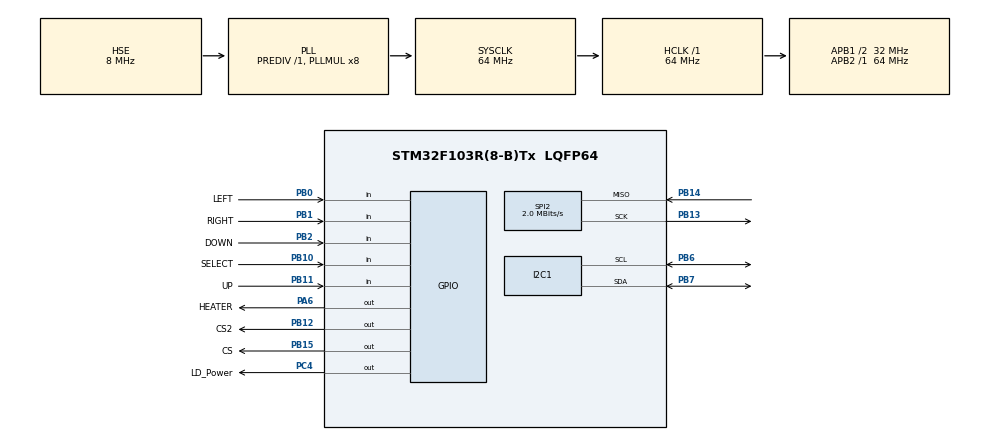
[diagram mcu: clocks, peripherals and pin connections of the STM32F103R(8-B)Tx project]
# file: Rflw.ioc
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FREERTOS.INCLUDE_xQueueGetMutexHolder=1
FREERTOS.Mutexes01=I2CMutex,Dynamic,NULL;xLCDMutex,Dynamic,NULL;SPIMutex,Dynamic,NULL
FREERTOS.Tasks01=systemMonitor,3,128,systemMonitorTask,Default,NULL,Dynamic,NULL,NULL;input,-2,128,inputTask,As external,NULL,Dynamic,NULL,NULL;menu,-3,128,menuTask,As external,NULL,Dynamic,NULL,NULL;control,1,128,controlTask,As external,NULL,Dynamic,NULL,NULL;LCD,-3,128,LCDTask,As external,NULL,Dynamic,NULL,NULL
FREERTOS.configCHECK_FOR_STACK_OVERFLOW=1
FREERTOS.configTOTAL_HEAP_SIZE=5120
I2C1.I2C_Mode=I2C_Fast
Mcu.Family=STM32F1
Mcu.Name=STM32F103R(8-B)Tx
Mcu.Package=LQFP64
NVIC.PriorityGroup=NVIC_PRIORITYGROUP_4
NVIC.SPI2_IRQn=true\:10\:0\:true\:false\:true\:true\:true\:true
NVIC.TIM1_UP_IRQn=true\:0\:0\:false\:false\:true\:false\:false\:true
NVIC.TimeBase=TIM1_UP_IRQn
NVIC.TimeBaseIP=TIM1
PA13.Mode=Trace_Asynchronous_SW
PA13.Signal=SYS_JTMS-SWDIO
PA14.Mode=Trace_Asynchronous_SW
PA14.Signal=SYS_JTCK-SWCLK
PA6.GPIO_Label=HEATER
PA6.PinState=GPIO_PIN_SET
PA6.Signal=GPIO_Output
PB0.GPIO_Label=LEFT
PB0.Signal=GPIO_Input
PB1.GPIO_Label=RIGHT
PB1.Signal=GPIO_Input
PB10.GPIO_Label=SELECT
PB10.GPIO_PuPd=GPIO_PULLUP
PB10.Signal=GPIO_Input
PB11.GPIO_Label=UP
PB11.GPIO_PuPd=GPIO_PULLUP
PB11.Signal=GPIO_Input
PB12.GPIO_Label=CS2
PB12.GPIO_Speed=GPIO_SPEED_FREQ_HIGH
PB12.PinState=GPIO_PIN_SET
PB12.Signal=GPIO_Output
PB13.Mode=RX_Only_Simplex_Unidirect_Master
PB13.Signal=SPI2_SCK
PB14.Mode=RX_Only_Simplex_Unidirect_Master
PB14.Signal=SPI2_MISO
PB15.GPIO_Label=CS
PB15.GPIO_Speed=GPIO_SPEED_FREQ_HIGH
PB15.PinState=GPIO_PIN_SET
PB15.Signal=GPIO_Output
PB2.GPIO_Label=DOWN
PB2.GPIO_PuPd=GPIO_PULLUP
PB2.Signal=GPIO_Input
PB3.Mode=Trace_Asynchronous_SW
PB3.Signal=SYS_JTDO-TRACESWO
PB6.Mode=I2C
PB6.Signal=I2C1_SCL
PB7.Mode=I2C
PB7.Signal=I2C1_SDA
PC14-OSC32_IN.Mode=LSE-External-Oscillator
PC14-OSC32_IN.Signal=RCC_OSC32_IN
PC15-OSC32_OUT.Mode=LSE-External-Oscillator
PC15-OSC32_OUT.Signal=RCC_OSC32_OUT
PC4.GPIO_Label=LD_Power
PC4.GPIO_ModeDefaultOutputPP=GPIO_MODE_OUTPUT_OD
PC4.PinState=GPIO_PIN_SET
PC4.Signal=GPIO_Output
PD0-OSC_IN.Mode=HSE-External-Oscillator
PD0-OSC_IN.Signal=RCC_OSC_IN
PD1-OSC_OUT.Mode=HSE-External-Oscillator
PD1-OSC_OUT.Signal=RCC_OSC_OUT
ProjectManager.HeapSize=0x200
ProjectManager.StackSize=0x400
ProjectManager.TargetToolchain=STM32CubeIDE
RCC.AHBFreq_Value=64000000
RCC.APB1CLKDivider=RCC_HCLK_DIV2
RCC.APB1Freq_Value=32000000
RCC.APB1TimFreq_Value=64000000
RCC.APB2Freq_Value=64000000
RCC.APB2TimFreq_Value=64000000
RCC.EnbaleCSS=true
RCC.HCLKFreq_Value=64000000
RCC.PLLMUL=RCC_PLL_MUL8
RCC.PLLSourceVirtual=RCC_PLLSOURCE_HSE
RCC.SYSCLKFreq_VALUE=64000000
RCC.SYSCLKSource=RCC_SYSCLKSOURCE_PLLCLK
RCC.USBFreq_Value=64000000
SPI2.BaudRatePrescaler=SPI_BAUDRATEPRESCALER_16
SPI2.CalculateBaudRate=2.0 MBits/s
SPI2.DataSize=SPI_DATASIZE_16BIT
SPI2.Direction=SPI_DIRECTION_2LINES_RXONLY
SPI2.Mode=SPI_MODE_MASTER
SPI2.VirtualType=VM_MASTER
VP_FREERTOS_VS_CMSIS_V1.Mode=CMSIS_V1
VP_SYS_VS_tim1.Mode=TIM1
board=custom

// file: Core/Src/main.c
/* USER CODE BEGIN Header */
/**
  ******************************************************************************
  * @file           : main.c
  * @brief          : Main program body
  ******************************************************************************
  * @attention
  *
  * <h2><center>&copy; Copyright (c) 2019 STMicroelectronics.
  * All rights reserved.</center></h2>
  *
  * This software component is licensed by ST under BSD 3-Clause license,
  * the "License"; You may not use this file except in compliance with the
  * License. You may obtain a copy of the License at:
  *                        opensource.org/licenses/BSD-3-Clause
  *
  ******************************************************************************
  */
/* USER CODE END Header */

#include "main.h"
#include "FreeRTOS.h"
#include "task.h"
#include "queue.h"
#include "semphr.h"

#include "config.h"

I2C_HandleTypeDef hi2c1;

SPI_HandleTypeDef hspi2;

#ifdef ENABLE_WWDG
WWDG_HandleTypeDef hwwdg;
#endif /* ENABLE_WWDG */

TaskHandle_t systemMonitorHandle;
TaskHandle_t inputHandle;
TaskHandle_t menuHandle;
TaskHandle_t controlHandle;
TaskHandle_t LCDHandle;

void SystemClock_Config(void);
static void MX_GPIO_Init(void);
static void MX_I2C1_Init(void);
static void MX_SPI2_Init(void);
#ifdef ENABLE_WWDG
static void MX_WWDG_Init(void);
#endif /* ENABLE_WWDG */
void systemMonitorTask(void * argument);
extern void vInputTask(void * argument);
extern void vMenuTask(void * argument);
extern void vControlTask(void * argument);
extern void vLCDTask(void * argument);

void InitSystem(void) {
	SystemClock_Config();

	MX_GPIO_Init();
	MX_I2C1_Init();
	MX_SPI2_Init();
	#ifdef ENABLE_WWDG
	MX_WWDG_Init();
	#endif /* ENABLE_WWDG */

//	HAL_SPI_RegisterCallback();
}

void InitOS(void) {
	xSystemMonitorTask = xTaskCreateStatic(systemMonitorTask, SYSTEM_MONITOR_NAME, SYSTEM_MONITOR_STACK_SIZE, NULL, SYSTEM_MONITOR_PRIORITY, xSystemMonitorStack, &xSystemMonitorBuffer);

	xInputHandlerTask = xTaskCreateStatic(vInputTask, INPUT_HANDLER_NAME, INPUT_HANDLER_STACK_SIZE, NULL, INPUT_HANDLER_PRIORITY, xInputHandlerStack, &xInputHandlerBuffer);

	xLCDTask = xTaskCreateStatic(vLCDTask, LCD_NAME, LCD_STACK_SIZE, NULL, LCD_PRIORITY, xLCDStack, &xLCDBuffer);

	xMenuTask = xTaskCreateStatic(vMenuTask, MENU_NAME, MENU_STACK_SIZE, NULL, MENU_PRIORITY, xMenuStack, &xMenuBuffer);

	xControlTask = xTaskCreateStatic(vControlTask, CONTROL_NAME, CONTROL_STACK_SIZE, NULL, CONTROL_PRIORITY, xControlStack, &xControlBuffer);

	xControlTask =  xTaskCreateStatic(vControlTask, CONTROL_NAME, CONTROL_STACK_SIZE, NULL, CONTROL_PRIORITY, xControlStack, &xControlBuffer);

	xI2CMutex = xSemaphoreCreateMutexStatic(&xI2CMutexBuffer);

	xSPIMutex = xSemaphoreCreateMutexStatic(&xSPIMutexBuffer);

	xLCDMutex = xSemaphoreCreateMutexStatic(&xLCDMutexBuffer);

	modeEventGroup = xEventGroupCreate();
	stateEventGroup = xEventGroupCreate();

	/* Start scheduler */
	vTaskStartScheduler();
}

void SystemClock_Config(void) {
	RCC_OscInitTypeDef RCC_OscInitStruct = {0};
	RCC_ClkInitTypeDef RCC_ClkInitStruct = {0};

	/** Initializes the CPU, AHB and APB busses clocks
	 */
	RCC_OscInitStruct.OscillatorType = RCC_OSCILLATORTYPE_HSE;
	RCC_OscInitStruct.HSEState = RCC_HSE_ON;
	RCC_OscInitStruct.HSEPredivValue = RCC_HSE_PREDIV_DIV1;
	RCC_OscInitStruct.HSIState = RCC_HSI_ON;
	RCC_OscInitStruct.PLL.PLLState = RCC_PLL_ON;
	RCC_OscInitStruct.PLL.PLLSource = RCC_PLLSOURCE_HSE;
	RCC_OscInitStruct.PLL.PLLMUL = RCC_PLL_MUL8;
	if (HAL_RCC_OscConfig(&RCC_OscInitStruct) != HAL_OK) {
		Error_Handler();
	}
	/** Initializes the CPU, AHB and APB busses clocks
	 */
	RCC_ClkInitStruct.ClockType = RCC_CLOCKTYPE_HCLK|RCC_CLOCKTYPE_SYSCLK
								|RCC_CLOCKTYPE_PCLK1|RCC_CLOCKTYPE_PCLK2;
	RCC_ClkInitStruct.SYSCLKSource = RCC_SYSCLKSOURCE_PLLCLK;
	RCC_ClkInitStruct.AHBCLKDivider = RCC_SYSCLK_DIV1;
	RCC_ClkInitStruct.APB1CLKDivider = RCC_HCLK_DIV2;
	RCC_ClkInitStruct.APB2CLKDivider = RCC_HCLK_DIV1;

	if (HAL_RCC_ClockConfig(&RCC_ClkInitStruct, FLASH_LATENCY_2) != HAL_OK) {
		Error_Handler();
	}
	/** Enables the Clock Security System
	 */
	HAL_RCC_EnableCSS();
}

static void MX_I2C1_Init(void) {
	hi2c1.Instance = I2C1;
	hi2c1.Init.ClockSpeed = 400000;
	hi2c1.Init.DutyCycle = I2C_DUTYCYCLE_2;
	hi2c1.Init.OwnAddress1 = 0;
	hi2c1.Init.AddressingMode = I2C_ADDRESSINGMODE_7BIT;
	hi2c1.Init.DualAddressMode = I2C_DUALADDRESS_DISABLE;
	hi2c1.Init.OwnAddress2 = 0;
	hi2c1.Init.GeneralCallMode = I2C_GENERALCALL_DISABLE;
	hi2c1.Init.NoStretchMode = I2C_NOSTRETCH_DISABLE;
	if (HAL_I2C_Init(&hi2c1) != HAL_OK) {
		Error_Handler();
	}
}

static void MX_SPI2_Init(void) {
	/* SPI2 parameter configuration*/
	hspi2.Instance = SPI2;
	hspi2.Init.Mode = SPI_MODE_MASTER;
	hspi2.Init.Direction = SPI_DIRECTION_2LINES_RXONLY;
	hspi2.Init.DataSize = SPI_DATASIZE_16BIT;
	hspi2.Init.CLKPolarity = SPI_POLARITY_LOW;
	hspi2.Init.CLKPhase = SPI_PHASE_1EDGE;
	hspi2.Init.NSS = SPI_NSS_SOFT;
	hspi2.Init.BaudRatePrescaler = SPI_BAUDRATEPRESCALER_16;
	hspi2.Init.FirstBit = SPI_FIRSTBIT_MSB;
	hspi2.Init.TIMode = SPI_TIMODE_DISABLE;
	hspi2.Init.CRCCalculation = SPI_CRCCALCULATION_DISABLE;
	hspi2.Init.CRCPolynomial = 10;
	if (HAL_SPI_Init(&hspi2) != HAL_OK) {
		Error_Handler();
	}

}

#ifdef ENABLE_WWDG
static void MX_WWDG_Init(void) {
	hwwdg.Instance = WWDG;
	hwwdg.Init.Prescaler = WWDG_PRESCALER_8;
	hwwdg.Init.Window = 96;
	hwwdg.Init.Counter = 127;
	hwwdg.Init.EWIMode = WWDG_EWI_DISABLE;
	if (HAL_WWDG_Init(&hwwdg) != HAL_OK) {
		Error_Handler();
	}
}
#endif /* ENABLE_WWDG */

static void MX_GPIO_Init(void) {
	GPIO_InitTypeDef GPIO_InitStruct = {0};

	/* GPIO Ports Clock Enable */
	__HAL_RCC_GPIOC_CLK_ENABLE();
	__HAL_RCC_GPIOD_CLK_ENABLE();
	__HAL_RCC_GPIOA_CLK_ENABLE();
	__HAL_RCC_GPIOB_CLK_ENABLE();

	/*Configure GPIO pin Output Level */
	HAL_GPIO_WritePin(HEATER_GPIO_Port, HEATER_Pin, GPIO_PIN_SET);

	/*Configure GPIO pin Output Level */
	HAL_GPIO_WritePin(LD_Power_GPIO_Port, LD_Power_Pin, GPIO_PIN_SET);

	/*Configure GPIO pin Output Level */
	HAL_GPIO_WritePin(GPIOB, CS2_Pin|CS_Pin, GPIO_PIN_SET);

	/*Configure GPIO pin : HEATER_Pin */
	GPIO_InitStruct.Pin = HEATER_Pin;
	GPIO_InitStruct.Mode = GPIO_MODE_OUTPUT_PP;
	GPIO_InitStruct.Pull = GPIO_NOPULL;
	GPIO_InitStruct.Speed = GPIO_SPEED_FREQ_LOW;
	HAL_GPIO_Init(HEATER_GPIO_Port, &GPIO_InitStruct);

	/*Configure GPIO pin : LD_Power_Pin */
	GPIO_InitStruct.Pin = LD_Power_Pin;
	GPIO_InitStruct.Mode = GPIO_MODE_OUTPUT_OD;
	GPIO_InitStruct.Pull = GPIO_NOPULL;
	GPIO_InitStruct.Speed = GPIO_SPEED_FREQ_LOW;
	HAL_GPIO_Init(LD_Power_GPIO_Port, &GPIO_InitStruct);

	/*Configure GPIO pins : LEFT_Pin RIGHT_Pin */
	GPIO_InitStruct.Pin = LEFT_Pin|RIGHT_Pin;
	GPIO_InitStruct.Mode = GPIO_MODE_INPUT;
	GPIO_InitStruct.Pull = GPIO_NOPULL;
	HAL_GPIO_Init(GPIOB, &GPIO_InitStruct);

	/*Configure GPIO pins : DOWN_Pin SELECT_Pin UP_Pin */
	GPIO_InitStruct.Pin = DOWN_Pin|SELECT_Pin|UP_Pin;
	GPIO_InitStruct.Mode = GPIO_MODE_INPUT;
	GPIO_InitStruct.Pull = GPIO_PULLUP;
	HAL_GPIO_Init(GPIOB, &GPIO_InitStruct);

	/*Configure GPIO pins : CS2_Pin CS_Pin */
	GPIO_InitStruct.Pin = CS2_Pin|CS_Pin;
	GPIO_InitStruct.Mode = GPIO_MODE_OUTPUT_PP;
	GPIO_InitStruct.Pull = GPIO_NOPULL;
	GPIO_InitStruct.Speed = GPIO_SPEED_FREQ_HIGH;
	HAL_GPIO_Init(GPIOB, &GPIO_InitStruct);

}

void systemMonitorTask(void * argument){
	// Every 48ms the window watchdog has the to refreshed, else the System will be restarted
	const TickType_t xDelay = 48 / portTICK_PERIOD_MS; // 48ms -
  	/* Infinite loop */
	while(1) {
		vTaskDelay(xDelay);
	#ifdef ENABLE_WWDG
		HAL_WWDG_Refresh(&hwwdg);
	#endif /* ENABLE_WWDG */
	}
}

 /**
  * @brief  Period elapsed callback in non blocking mode
  * @note   This function is called  when TIM1 interrupt took place, inside
  * HAL_TIM_IRQHandler(). It makes a direct call to HAL_IncTick() to increment
  * a global variable "uwTick" used as application time base.
  * @param  htim : TIM handle
  * @retval None
  */
void HAL_TIM_PeriodElapsedCallback(TIM_HandleTypeDef *htim) {
	if (htim->Instance == TIM1) {
		HAL_IncTick();
	}
}

void Error_Handler(void) {
	/* USER CODE BEGIN Error_Handler_Debug */
	/* User can add his own implementation to report the HAL error return state */
	while(1) {
		HAL_GPIO_TogglePin(LD_Power_GPIO_Port, LD_Power_Pin);
		HAL_Delay(100);
	}
	/* USER CODE END Error_Handler_Debug */
}

/************************ (C) COPYRIGHT STMicroelectronics *****END OF FILE****/

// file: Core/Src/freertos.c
/* USER CODE BEGIN Header */
/**
  ******************************************************************************
  * File Name          : freertos.c
  * Description        : Code for freertos applications
  ******************************************************************************
  * @attention
  *
  * <h2><center>&copy; Copyright (c) 2019 STMicroelectronics.
  * All rights reserved.</center></h2>
  *
  * This software component is licensed by ST under Ultimate Liberty license
  * SLA0044, the "License"; You may not use this file except in compliance with
  * the License. You may obtain a copy of the License at:
  *                             www.st.com/SLA0044
  *
  ******************************************************************************
  */
/* USER CODE END Header */

#include "FreeRTOS.h"
#include "task.h"
#include "main.h"

/* GetIdleTaskMemory prototype (linked to static allocation support) */
void vApplicationGetIdleTaskMemory( StaticTask_t **ppxIdleTaskTCBBuffer, StackType_t **ppxIdleTaskStackBuffer, uint32_t *pulIdleTaskStackSize );

/* USER CODE BEGIN 4 */
__weak void vApplicationStackOverflowHook( TaskHandle_t xTask, char * pcTaskName )
{
   /* Run time stack overflow checking is performed if
   configCHECK_FOR_STACK_OVERFLOW is defined to 1 or 2. This hook function is
   called if a stack overflow is detected. */
   while (1)
   {
     /* code */
   }

}
/* USER CODE END 4 */

/* USER CODE BEGIN GET_IDLE_TASK_MEMORY */
static StaticTask_t xIdleTaskTCBBuffer;
static StackType_t xIdleStack[configMINIMAL_STACK_SIZE];

void vApplicationGetIdleTaskMemory( StaticTask_t **ppxIdleTaskTCBBuffer, StackType_t **ppxIdleTaskStackBuffer, uint32_t *pulIdleTaskStackSize )
{
  *ppxIdleTaskTCBBuffer = &xIdleTaskTCBBuffer;
  *ppxIdleTaskStackBuffer = &xIdleStack[0];
  *pulIdleTaskStackSize = configMINIMAL_STACK_SIZE;
  /* place for user code */
}
/* USER CODE END GET_IDLE_TASK_MEMORY */

/************************ (C) COPYRIGHT STMicroelectronics *****END OF FILE****/
